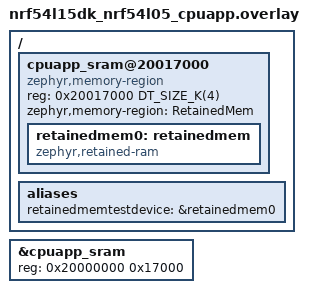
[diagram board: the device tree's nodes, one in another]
/ {
	cpuapp_sram@20017000 {
		compatible = "zephyr,memory-region", "mmio-sram";
		reg = <0x20017000 DT_SIZE_K(4)>;
		zephyr,memory-region = "RetainedMem";
		status = "okay";

		retainedmem0: retainedmem {
			compatible = "zephyr,retained-ram";
			status = "okay";
		};
	};

	aliases {
		retainedmemtestdevice = &retainedmem0;
	};
};

&cpuapp_sram {
	/* Shrink SRAM size to avoid overlap with retained memory region:
	 * 96 - 4 = 92KB = 0x17000
	 */
	reg = <0x20000000 0x17000>;
	ranges = <0x0 0x20000000 0x17000>;
};
